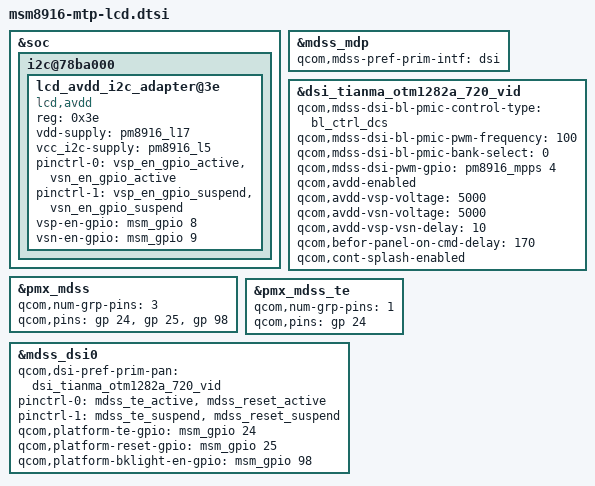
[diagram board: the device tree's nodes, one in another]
/* Copyright (c) 2014, The Linux Foundation. All rights reserved.
 *
 * This program is free software; you can redistribute it and/or modify
 * it under the terms of the GNU General Public License version 2 and
 * only version 2 as published by the Free Software Foundation.
 *
 * This program is distributed in the hope that it will be useful,
 * but WITHOUT ANY WARRANTY; without even the implied warranty of
 * MERCHANTABILITY or FITNESS FOR A PARTICULAR PURPOSE.  See the
 * GNU General Public License for more details.
 */

#include "./msm8916-lcd-pinctrl.dtsi"
#include "dsi-tianma-panel-otm1282a-720p-video.dtsi"
#include "dsi-n918x-cs-panel-nt35592-720p-video.dtsi"
#include "dsi-n918x-lianchuang-panel-nt35592-720p-video.dtsi"
#include "dsi-n918x-success-panel-hx8392b-720p-video.dtsi"
#include "../../dsi-panel-jdi-1080p-video.dtsi"

&soc {
	i2c@78ba000 { /* BLSP1 QUP6 */
		lcd_avdd_i2c_adapter@3e {
			compatible = "lcd,avdd";
			reg = <0x3e>;
			vdd-supply = <&pm8916_l17>;
			vcc_i2c-supply = <&pm8916_l5>;
			pinctrl-0 = <&vsp_en_gpio_active &vsn_en_gpio_active>;
			pinctrl-1 = <&vsp_en_gpio_suspend &vsn_en_gpio_suspend>;
			vsp-en-gpio    = <&msm_gpio 8 0x00>;
			vsn-en-gpio    = <&msm_gpio 9 0x00>;
		};
	};
};

&mdss_mdp {
	qcom,mdss-pref-prim-intf = "dsi";
};

&dsi_tianma_otm1282a_720_vid {
	qcom,mdss-dsi-bl-pmic-control-type = "bl_ctrl_dcs";
	qcom,mdss-dsi-bl-pmic-pwm-frequency = <100>;
	qcom,mdss-dsi-bl-pmic-bank-select = <0>;
	qcom,mdss-dsi-pwm-gpio = <&pm8916_mpps 4 0>;
    qcom,avdd-enabled;
    qcom,avdd-vsp-voltage = <5000>;
    qcom,avdd-vsn-voltage = <5000>;
    qcom,avdd-vsp-vsn-delay = <10>;
    qcom,befor-panel-on-cmd-delay = <170>;
	qcom,cont-splash-enabled;
};

&pmx_mdss {
       qcom,num-grp-pins = <3>;
       qcom,pins = <&gp 24>, <&gp 25>, <&gp 98>;
};

&pmx_mdss_te {
       qcom,num-grp-pins = <1>;
       qcom,pins = <&gp 24>;
};

&mdss_dsi0 {
       qcom,dsi-pref-prim-pan = <&dsi_tianma_otm1282a_720_vid>;
       pinctrl-names = "mdss_default", "mdss_sleep";
	   pinctrl-0 = <&mdss_te_active &mdss_reset_active>;
	   pinctrl-1 = <&mdss_te_suspend &mdss_reset_suspend>;


       //qcom,platform-enable-gpio = <&msm_gpio 97 0>;
       qcom,platform-te-gpio = <&msm_gpio 24 0>;
       qcom,platform-reset-gpio = <&msm_gpio 25 0>;
       qcom,platform-bklight-en-gpio = <&msm_gpio 98 0>;
};
